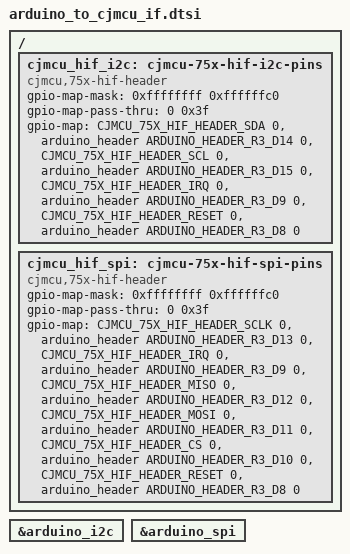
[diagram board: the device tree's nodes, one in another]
/*
 * SPDX-FileCopyrightText: Copyright (c) 2024-2026 TiaC Systems
 * SPDX-License-Identifier: Apache-2.0
 */

cjmcu_i2c: &arduino_i2c {};
cjmcu_spi: &arduino_spi {};

#include <zephyr/dt-bindings/gpio/arduino-header-r3.h>
#include <zephyr/dt-bindings/gpio/cjmcu-75x-hif-header.h>

/ {
	cjmcu_hif_i2c: cjmcu-75x-hif-i2c-pins {
		compatible = "cjmcu,75x-hif-header";
		#gpio-cells = <2>;
		gpio-map-mask = <0xffffffff 0xffffffc0>;
		gpio-map-pass-thru = <0 0x3f>;
		gpio-map = <CJMCU_75X_HIF_HEADER_SDA 0 &arduino_header ARDUINO_HEADER_R3_D14 0>,
			   <CJMCU_75X_HIF_HEADER_SCL 0 &arduino_header ARDUINO_HEADER_R3_D15 0>,
			   /* I2C/nSPI signal set to high (VCC) */
			   <CJMCU_75X_HIF_HEADER_IRQ 0 &arduino_header ARDUINO_HEADER_R3_D9 0>,
			   /* NC/SO signal not connected (required) */
			   /* A1/SI signal set to I2C addr. select */
			   /* A0/CS signal set to I2C addr. select */
			   <CJMCU_75X_HIF_HEADER_RESET 0 &arduino_header ARDUINO_HEADER_R3_D8 0>;
	};

	cjmcu_hif_spi: cjmcu-75x-hif-spi-pins {
		compatible = "cjmcu,75x-hif-header";
		#gpio-cells = <2>;
		gpio-map-mask = <0xffffffff 0xffffffc0>;
		gpio-map-pass-thru = <0 0x3f>;
		gpio-map = /* SDA/NC signal not connected (required) */
			   <CJMCU_75X_HIF_HEADER_SCLK 0 &arduino_header ARDUINO_HEADER_R3_D13 0>,
			   /* I2C/nSPI signal set to low (GND) */
			   <CJMCU_75X_HIF_HEADER_IRQ 0 &arduino_header ARDUINO_HEADER_R3_D9 0>,
			   <CJMCU_75X_HIF_HEADER_MISO 0 &arduino_header ARDUINO_HEADER_R3_D12 0>,
			   <CJMCU_75X_HIF_HEADER_MOSI 0 &arduino_header ARDUINO_HEADER_R3_D11 0>,
			   <CJMCU_75X_HIF_HEADER_CS 0 &arduino_header ARDUINO_HEADER_R3_D10 0>,
			   <CJMCU_75X_HIF_HEADER_RESET 0 &arduino_header ARDUINO_HEADER_R3_D8 0>;
	};
};
